# STM32U585 register map
File version: 1.4
CPU: CM33 r0p1, little endian, MPU, FPU, 4 interrupt priority bits
Registers are 32-bit, read-write, reset 0x0 unless marked. A register's access mark holds for its fields unless they carry their own. Offsets are from the block's base; [hi:lo] are bit positions; {n}, {i} and the like mark numbered series; 'fields as' and 'values as' point back to an identical list.

## LPGPIO1
Base 0x46020000
Same registers: SEC_LPGPIO1 0x56020000
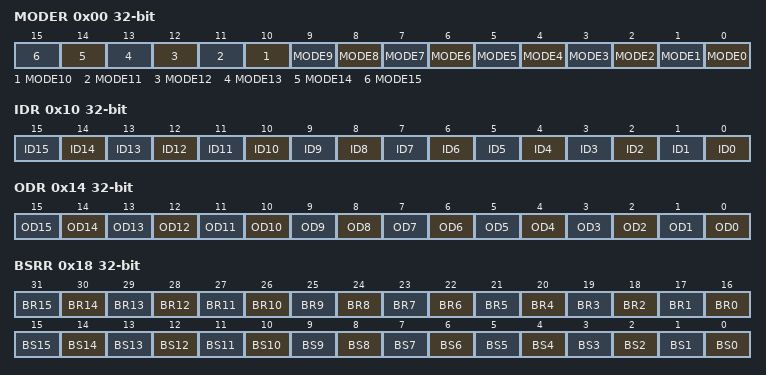
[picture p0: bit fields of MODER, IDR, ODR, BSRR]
0x00 MODER — LPGPIO port mode register
  [n] MODE{n} (n=0..15) — MODE{n}
0x10 IDR ro — LPGPIO port input data register
  [n] ID{n} (n=0..15) — ID{n}
0x14 ODR — LPGPIO port output data register
  [n] OD{n} (n=0..15) — OD{n}
0x18 BSRR wo — LPGPIO port bit set/reset register
  [n+16] BR{n} (n=0..15) — BR{n}
  [n] BS{n} (n=0..15) — BS{n}
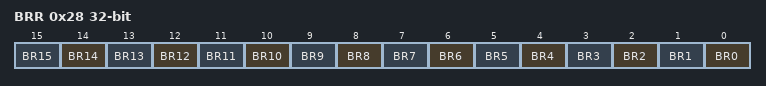
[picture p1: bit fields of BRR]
0x28 BRR wo — LPGPIO port bit reset register
  [n] BR{n} (n=0..15) — BR{n}

## OCTOSPIM — OCTOSPI I/O manager
Base 0x420C4000
Same registers: SEC_OCTOSPIM 0x520C4000
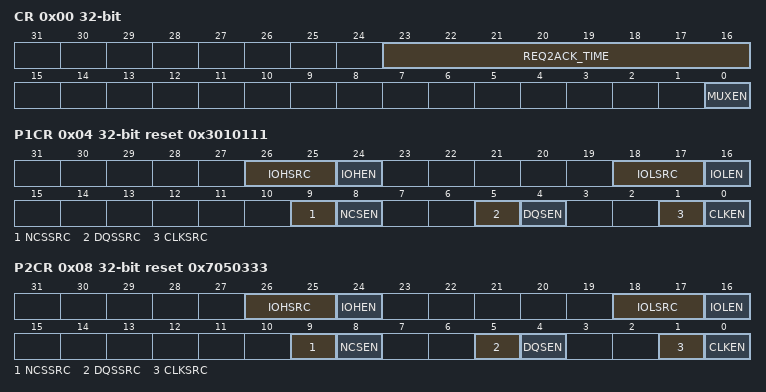
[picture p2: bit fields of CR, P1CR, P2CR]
0x00 CR — control register
  [23:16] REQ2ACK_TIME — REQ to ACK time
  [0] MUXEN — Multiplexed mode enable
0x04 P1CR reset 0x3010111 — OCTOSPI I/O manager Port 1 configuration register
  [26:25] IOHSRC — IOHSR
  [24] IOHEN
  [18:17] IOLSRC
  [16] IOLEN
  [9] NCSSRC
  [8] NCSEN
  [5] DQSSRC
  [4] DQSEN
  [1] CLKSRC
  [0] CLKEN
0x08 P2CR reset 0x7050333 — OCTOSPI I/O manager Port 2 configuration register
  fields as P1CR

## ADC12_Common — ADC common registers
Base 0x42028300
Same registers: SEC_ADC12 0x52028300
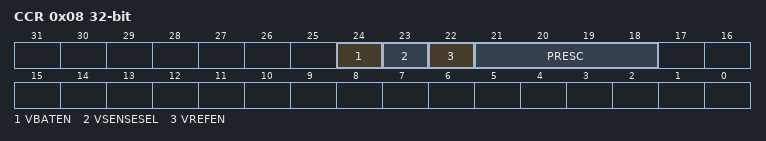
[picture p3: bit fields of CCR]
0x08 CCR — ADC_CCR system control register
  [24] VBATEN — VBAT enable This bit is set and cleared by software to control the VBAT channel. Note: The software is allowed to write this bit only when the ADCs are disabled (ADCAL = 0, JADSTART = 0, ADSTART = 0, ADSTP = 0, ADDIS = 0 and ADEN = 0).
    0=Disabled (VBAT channel disabled); 1=Enabled (VBAT channel enabled)
  [23] VSENSESEL — Temperature sensor voltage selection This bit is set and cleared by software to control the temperature sensor channel. Note: The software is allowed to write this bit only when the ADCs are disabled (ADCAL = 0, JADSTART = 0, ADSTART = 0, ADSTP = 0, ADDIS = 0 and ADEN = 0).
    0=Disabled (Temperature sensor channel disabled); 1=Enabled (Temperature sensor channel enabled)
  [22] VREFEN — VREFINT enable This bit is set and cleared by software to enable/disable the VREFINT buffer. Note: The software is allowed to write this bit only when the ADCs are disabled (ADCAL = 0, JADSTART = 0, ADSTART = 0, ADSTP = 0, ADDIS = 0 and ADEN = 0).
    0=Disabled (VREFINT channel disabled); 1=Enabled (VREFINT channel enabled)
  [21:18] PRESC — ADC prescaler These bits are set and cleared by software to select the frequency of the ADC clock. The clock is common to all ADCs. Others: Reserved, must not be used Note: The software is allowed to write this bit only when the ADCs are disabled (ADCAL = 0, JADSTART = 0, ADSTART = 0, ADSTP = 0, ADDIS = 0 and ADEN = 0).
    0=Div1 (Input ADC clock not divided); 1=Div2 (Input ADC clock divided by 2); 2=Div4 (Input ADC clock divided by 4); 3=Div6 (Input ADC clock divided by 6); 4=Div8 (Input ADC clock divided by 8); 5=Div10 (Input ADC clock divided by 10); 6=Div12 (Input ADC clock divided by 12); 7=Div16 (Input ADC clock divided by 16); 8=Div32 (Input ADC clock divided by 32); 9=Div64 (Input ADC clock divided by 64); 10=Div128 (Input ADC clock divided by 128); 11=Div256 (Input ADC clock divided by 256)

## FMAC — Filter Math Accelerator
Base 0x40021400
Same registers: SEC_FMAC 0x50021400
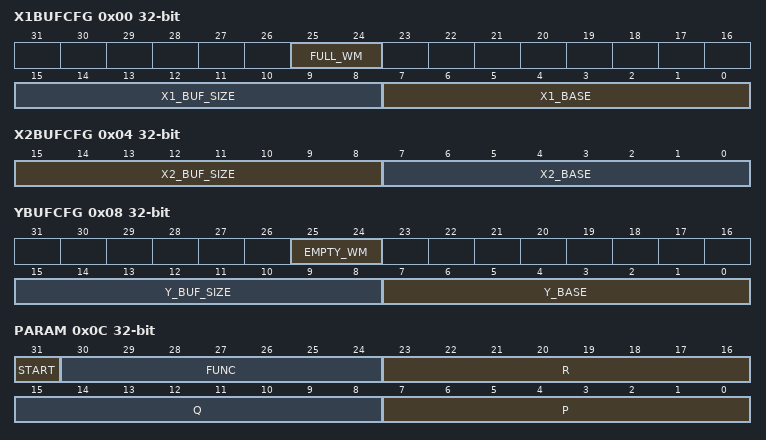
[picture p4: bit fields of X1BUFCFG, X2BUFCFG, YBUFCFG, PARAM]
0x00 X1BUFCFG — FMAC X1 Buffer Configuration register
  [25:24] FULL_WM — Watermark for buffer full flag
  [15:8] X1_BUF_SIZE — Allocated size of X1 buffer in 16-bit words
  [7:0] X1_BASE — Base address of X1 buffer
0x04 X2BUFCFG — FMAC X2 Buffer Configuration register
  [15:8] X2_BUF_SIZE — Size of X2 buffer in 16-bit words
  [7:0] X2_BASE — Base address of X2 buffer
0x08 YBUFCFG — FMAC Y Buffer Configuration register
  [25:24] EMPTY_WM — Watermark for buffer empty flag
  [15:8] Y_BUF_SIZE — Size of Y buffer in 16-bit words
  [7:0] Y_BASE — Base address of Y buffer
0x0C PARAM — FMAC Parameter register
  [31] START — Enable execution
  [30:24] FUNC — Function
  [23:16] R — Input parameter R
  [15:8] Q — Input parameter Q
  [7:0] P — Input parameter P
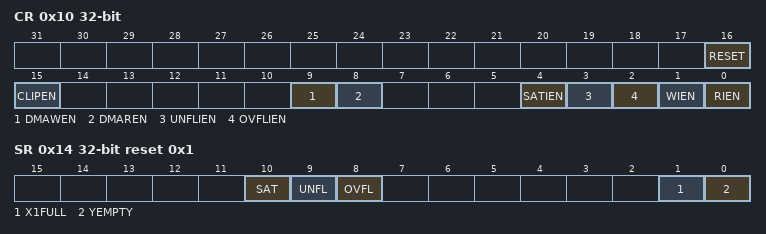
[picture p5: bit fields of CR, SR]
0x10 CR — FMAC Control register
  [16] RESET — Reset FMAC unit
  [15] CLIPEN — Enable clipping
  [9] DMAWEN — Enable DMA write channel requests
  [8] DMAREN — Enable DMA read channel requests
  [4] SATIEN — Enable saturation error interrupts
  [3] UNFLIEN — Enable underflow error interrupts
  [2] OVFLIEN — Enable overflow error interrupts
  [1] WIEN — Enable write interrupt
  [0] RIEN — Enable read interrupt
0x14 SR ro reset 0x1 — FMAC Status register
  [10] SAT — Saturation error flag
  [9] UNFL — Underflow error flag
  [8] OVFL — Overflow error flag
  [1] X1FULL — X1 buffer full flag
  [0] YEMPTY — Y buffer empty flag
0x18 WDATA wo — FMAC Write Data register
  [15:0] WDATA — Write data
0x1C RDATA ro — FMAC Read Data register
  [15:0] RDATA — Read data
